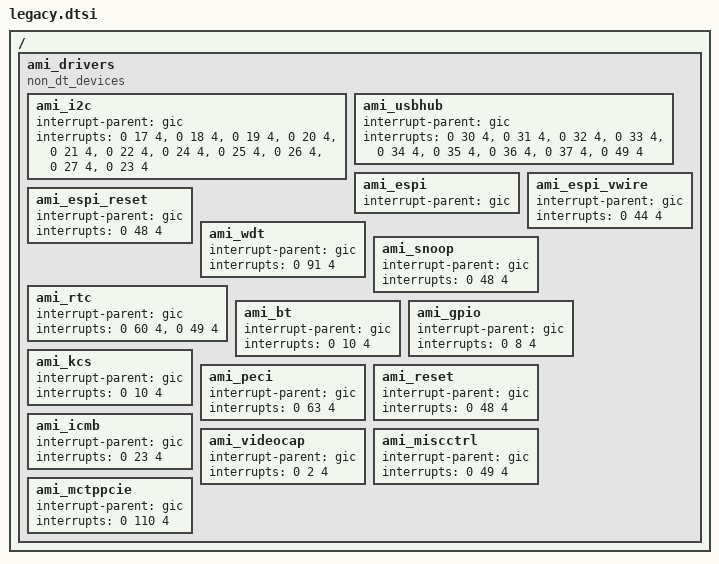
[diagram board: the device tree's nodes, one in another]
/  {	
	ami_drivers {

   		compatible = "non_dt_devices";
        	#address-cells = <0x1>;
        	#size-cells = <0x1>;
        	ranges;


     		ami_i2c{
            	interrupt-parent = <&gic>;
            	interrupts = <0 17 4>, <0 18 4>, <0 19 4>, <0 20 4>, <0 21 4>,
                         <0 22 4>, <0 24 4>, <0 25 4>, <0 26 4>, <0 27 4>,
                         <0 23 4>;
			};

 			ami_usbhub {
            	interrupt-parent = <&gic>;
            	interrupts = <0 30 4>, <0 31 4>,
                        <0 32 4>, <0 33 4>,
                        <0 34 4>, <0 35 4>,
                        <0 36 4>, <0 37 4>,
                        <0 49 4>;
			};


            ami_espi {
                interrupt-parent = <&gic>;
            };

            ami_espi_vwire {
                interrupt-parent = <&gic>;
                interrupts = <0 44 4>;
            };

            ami_espi_reset {
                interrupt-parent = <&gic>;
                interrupts = <0 48 4>;
            };
	    ami_wdt {
		interrupt-parent = <&gic>;
		interrupts = <0 91 4>;
	    };


			ami_snoop {
				interrupt-parent = <&gic>;
				interrupts = <0 48 4>;
			};

			ami_rtc {
				interrupt-parent = <&gic>;
				interrupts = <0 60 4>, <0 49 4>;
			};


			ami_bt {
				interrupt-parent = <&gic>;
				interrupts = <0 10 4>; 
			};



			ami_gpio  {
				interrupt-parent = <&gic>;
				interrupts = <0 8 4>;
			};


			ami_kcs  {
				interrupt-parent = <&gic>;
				interrupts = <0 10 4>;
			};

	
			ami_peci {
				interrupt-parent = <&gic>;
				interrupts = <0 63 4>;
			};

			ami_reset {
				interrupt-parent = <&gic>;
				interrupts = <0 48 4>;
			};

  			ami_icmb {
                interrupt-parent = <&gic>;
                interrupts = <0 23 4>;
            };

 			ami_videocap {
                interrupt-parent = <&gic>;
                interrupts = <0 2 4>;
            };
	
			 ami_miscctrl {
                interrupt-parent = <&gic>;
                interrupts = <0 49 4>;
            };
			ami_mctppcie {
                interrupt-parent = <&gic>;
                interrupts = <0 110 4>;
            };

	};

};
